# ARM_VBUSP register map
Vendor: Texas Instruments
Peripheral module from a debugger description file (folder 66AK2G0x_66AK2G1x).
Registers are 32-bit, read-only, reset values left out (the file's numbers can be read two ways) unless marked. A register's access mark holds for its fields unless they carry their own. Offsets are as the file gives them; lines under a group give offsets from that group; [hi:lo] are bit positions; {n}, {i} and the like mark numbered series; 'fields as' and 'values as' point back to an identical list; <NAME> marks a mode.

## ARM_VBUSP
0x00 ARM_PID
  [31:0] PID — Peripheral Identification Register for ARM Subsystem
0x04 ARM_INTC_PID
  [31:0] PID — Peripheral Identification Register for ARM INTC
0x14 STM_DISABLE rw
  [31:0] STM_DISABLE — Disable access to STM in ARM Subsystem
0x400 PD_CPU0_PTCMD wo
  [0] GO_CPU — CPU power domain GO transition.
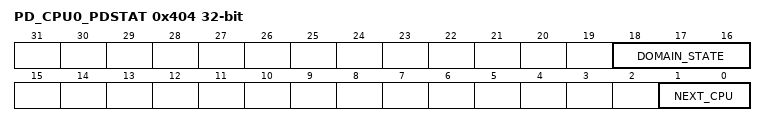
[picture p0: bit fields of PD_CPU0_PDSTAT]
0x404 PD_CPU0_PDSTAT
  [18:16] DOMAIN_STATE — Shows CPU power domain ACTUAL state. NEXT state should always match current domain state unless it is in transition. The only exception is when debug prevents powering down.
  [1:0] NEXT_CPU — Shows programmed CPU power domain NEXT state. These bits essentially reflect the NEXT state stored in the PDCTL shadow register inside the ARM CorePac. This field may not match the fields programmed into PDCTL until a GO transition command is issued
0x408 PD_CPU0_PDCTL rw
  [1:0] NEXT_CPU — CPU power domain NEXT state.
